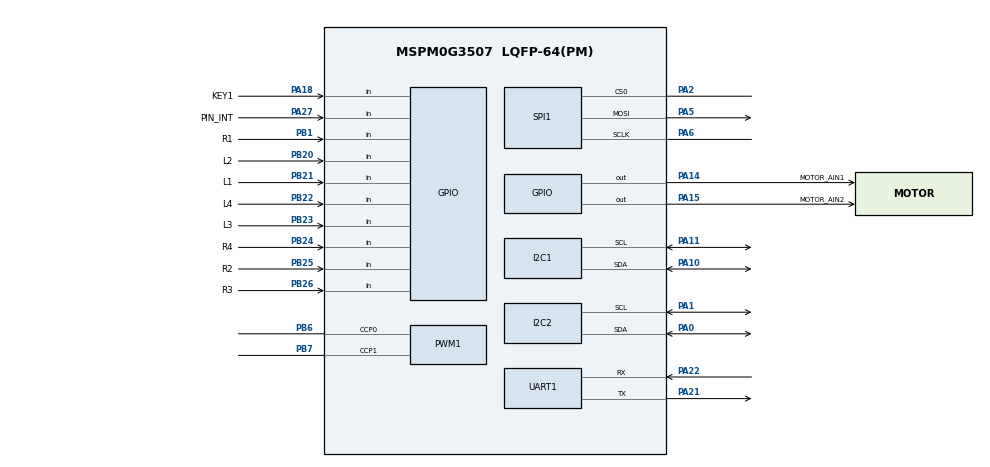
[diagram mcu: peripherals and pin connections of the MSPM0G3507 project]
/**
 * These arguments were used when this file was generated. They will be automatically applied on subsequent loads
 * via the GUI or CLI. Run CLI with '--help' for additional information on how to override these arguments.
 * @cliArgs --device "MSPM0G350X" --part "Default" --package "LQFP-64(PM)" --product "mspm0_sdk@2.10.00.04"
 * @v2CliArgs --device "MSPM0G3507" --package "LQFP-64(PM)" --product "mspm0_sdk@2.10.00.04"
 * @versions {"tool":"1.26.2+4477"}
 */

/**
 * Import the modules used in this configuration.
 */
const GPIO   = scripting.addModule("/ti/driverlib/GPIO", {}, false);
const GPIO1  = GPIO.addInstance();
const GPIO2  = GPIO.addInstance();
const GPIO3  = GPIO.addInstance();
const GPIO4  = GPIO.addInstance();
const GPIO5  = GPIO.addInstance();
const GPIO6  = GPIO.addInstance();
const GPIO7  = GPIO.addInstance();
const I2C    = scripting.addModule("/ti/driverlib/I2C", {}, false);
const I2C1   = I2C.addInstance();
const I2C2   = I2C.addInstance();
const PWM    = scripting.addModule("/ti/driverlib/PWM", {}, false);
const PWM1   = PWM.addInstance();
const SPI    = scripting.addModule("/ti/driverlib/SPI", {}, false);
const SPI1   = SPI.addInstance();
const SYSCTL = scripting.addModule("/ti/driverlib/SYSCTL");
const TIMER  = scripting.addModule("/ti/driverlib/TIMER", {}, false);
const TIMER1 = TIMER.addInstance();
const UART   = scripting.addModule("/ti/driverlib/UART", {}, false);
const UART1  = UART.addInstance();

/**
 * Write custom configuration values to the imported modules.
 */
GPIO1.port                           = "PORTB";
GPIO1.$name                          = "GPIO_RGB";
GPIO1.associatedPins[0].initialValue = "SET";
GPIO1.associatedPins[0].$name        = "GREEN";
GPIO1.associatedPins[0].assignedPin  = "27                                    ";

const Board = scripting.addModule("/ti/driverlib/Board", {}, false);

GPIO2.$name                              = "GPIO_BUTTON";
GPIO2.port                               = "PORTA";
GPIO2.associatedPins[0].$name            = "KEY1";
GPIO2.associatedPins[0].internalResistor = "PULL_DOWN";
GPIO2.associatedPins[0].direction        = "INPUT";
GPIO2.associatedPins[0].assignedPin      = "18";
GPIO2.associatedPins[0].pin.$assign      = "PA18";

GPIO3.port                          = "PORTA";
GPIO3.$name                         = "MOTOR_AIN";
GPIO3.associatedPins.create(2);
GPIO3.associatedPins[0].$name       = "MOTOR_AIN1";
GPIO3.associatedPins[0].assignedPin = "14";
GPIO3.associatedPins[0].pin.$assign = "PA14";
GPIO3.associatedPins[1].$name       = "MOTOR_AIN2";
GPIO3.associatedPins[1].assignedPin = "15";
GPIO3.associatedPins[1].pin.$assign = "PA15";

GPIO4.port                          = "PORTA";
GPIO4.$name                         = "MOTOR_BIN";
GPIO4.associatedPins.create(2);
GPIO4.associatedPins[0].assignedPin = "12";
GPIO4.associatedPins[0].$name       = "MOTOR_BIN1";
GPIO4.associatedPins[1].assignedPin = "13";
GPIO4.associatedPins[1].$name       = "MOTOR_BIN2";

GPIO5.$name                              = "GPIO_GRAY";
GPIO5.port                               = "PORTB";
GPIO5.associatedPins.create(8);
GPIO5.associatedPins[0].$name            = "L1";
GPIO5.associatedPins[0].direction        = "INPUT";
GPIO5.associatedPins[0].assignedPin      = "21";
GPIO5.associatedPins[0].internalResistor = "PULL_DOWN";
GPIO5.associatedPins[0].pin.$assign      = "PB21";
GPIO5.associatedPins[1].$name            = "L2";
GPIO5.associatedPins[1].direction        = "INPUT";
GPIO5.associatedPins[1].assignedPin      = "20";
GPIO5.associatedPins[1].internalResistor = "PULL_DOWN";
GPIO5.associatedPins[1].pin.$assign      = "PB20";
GPIO5.associatedPins[2].$name            = "L3";
GPIO5.associatedPins[2].direction        = "INPUT";
GPIO5.associatedPins[2].assignedPin      = "23";
GPIO5.associatedPins[2].internalResistor = "PULL_DOWN";
GPIO5.associatedPins[2].pin.$assign      = "PB23";
GPIO5.associatedPins[3].$name            = "L4";
GPIO5.associatedPins[3].direction        = "INPUT";
GPIO5.associatedPins[3].assignedPin      = "22";
GPIO5.associatedPins[3].internalResistor = "PULL_DOWN";
GPIO5.associatedPins[3].pin.$assign      = "PB22";
GPIO5.associatedPins[4].$name            = "R4";
GPIO5.associatedPins[4].direction        = "INPUT";
GPIO5.associatedPins[4].assignedPin      = "24";
GPIO5.associatedPins[4].internalResistor = "PULL_DOWN";
GPIO5.associatedPins[4].pin.$assign      = "PB24";
GPIO5.associatedPins[5].$name            = "R3";
GPIO5.associatedPins[5].direction        = "INPUT";
GPIO5.associatedPins[5].assignedPin      = "26";
GPIO5.associatedPins[5].internalResistor = "PULL_DOWN";
GPIO5.associatedPins[5].pin.$assign      = "PB26";
GPIO5.associatedPins[6].$name            = "R2";
GPIO5.associatedPins[6].direction        = "INPUT";
GPIO5.associatedPins[6].assignedPin      = "25";
GPIO5.associatedPins[6].internalResistor = "PULL_DOWN";
GPIO5.associatedPins[6].pin.$assign      = "PB25";
GPIO5.associatedPins[7].$name            = "R1";
GPIO5.associatedPins[7].direction        = "INPUT";
GPIO5.associatedPins[7].assignedPin      = "1";
GPIO5.associatedPins[7].internalResistor = "PULL_DOWN";
GPIO5.associatedPins[7].pin.$assign      = "PB1";

GPIO6.$name                               = "GPIO_MPU6050";
GPIO6.associatedPins[0].$name             = "PIN_INT";
GPIO6.associatedPins[0].direction         = "INPUT";
GPIO6.associatedPins[0].internalResistor  = "PULL_UP";
GPIO6.associatedPins[0].interruptEn       = true;
GPIO6.associatedPins[0].interruptPriority = "2";
GPIO6.associatedPins[0].polarity          = "FALL";
GPIO6.associatedPins[0].assignedPort      = "PORTA";
GPIO6.associatedPins[0].assignedPin       = "27";
GPIO6.associatedPins[0].pin.$assign       = "PA27";

GPIO7.$name                   = "GPIO_GRP_0";
GPIO7.associatedPins[0].$name = "PIN_0";

I2C1.$name                             = "I2C_OLED";
I2C1.basicEnableController             = true;
I2C1.basicControllerStandardBusSpeed   = "Fast";
I2C1.peripheral.$assign                = "I2C1";
I2C1.peripheral.sdaPin.$assign         = "PA10";
I2C1.peripheral.sclPin.$assign         = "PA11";
I2C1.sdaPinConfig.hideOutputInversion  = scripting.forceWrite(false);
I2C1.sdaPinConfig.onlyInternalResistor = scripting.forceWrite(false);
I2C1.sdaPinConfig.passedPeripheralType = scripting.forceWrite("Digital");
I2C1.sdaPinConfig.$name                = "ti_driverlib_gpio_GPIOPinGeneric2";
I2C1.sclPinConfig.hideOutputInversion  = scripting.forceWrite(false);
I2C1.sclPinConfig.onlyInternalResistor = scripting.forceWrite(false);
I2C1.sclPinConfig.passedPeripheralType = scripting.forceWrite("Digital");
I2C1.sclPinConfig.$name                = "ti_driverlib_gpio_GPIOPinGeneric3";

I2C2.$name                             = "I2C_MPU6050";
I2C2.basicEnableController             = true;
I2C2.basicControllerStandardBusSpeed   = "Fast";
I2C2.peripheral.$assign                = "I2C0";
I2C2.peripheral.sdaPin.$assign         = "PA0";
I2C2.peripheral.sclPin.$assign         = "PA1";
I2C2.sdaPinConfig.hideOutputInversion  = scripting.forceWrite(false);
I2C2.sdaPinConfig.onlyInternalResistor = scripting.forceWrite(false);
I2C2.sdaPinConfig.passedPeripheralType = scripting.forceWrite("Digital");
I2C2.sdaPinConfig.$name                = "ti_driverlib_gpio_GPIOPinGeneric4";
I2C2.sclPinConfig.hideOutputInversion  = scripting.forceWrite(false);
I2C2.sclPinConfig.onlyInternalResistor = scripting.forceWrite(false);
I2C2.sclPinConfig.passedPeripheralType = scripting.forceWrite("Digital");
I2C2.sclPinConfig.$name                = "ti_driverlib_gpio_GPIOPinGeneric5";

PWM1.$name                              = "PWM_MOTOR";
PWM1.pwmMode                            = "EDGE_ALIGN_UP";
PWM1.timerStartTimer                    = true;
PWM1.peripheral.$assign                 = "TIMG6";
PWM1.peripheral.ccp0Pin.$assign         = "PB6";
PWM1.peripheral.ccp1Pin.$assign         = "PB7";
PWM1.PWM_CHANNEL_0.$name                = "ti_driverlib_pwm_PWMTimerCC0";
PWM1.PWM_CHANNEL_0.dutyCycle            = 50;
PWM1.PWM_CHANNEL_1.$name                = "ti_driverlib_pwm_PWMTimerCC1";
PWM1.ccp0PinConfig.direction            = scripting.forceWrite("OUTPUT");
PWM1.ccp0PinConfig.hideOutputInversion  = scripting.forceWrite(false);
PWM1.ccp0PinConfig.onlyInternalResistor = scripting.forceWrite(false);
PWM1.ccp0PinConfig.passedPeripheralType = scripting.forceWrite("Digital");
PWM1.ccp0PinConfig.$name                = "ti_driverlib_gpio_GPIOPinGeneric0";
PWM1.ccp1PinConfig.direction            = scripting.forceWrite("OUTPUT");
PWM1.ccp1PinConfig.hideOutputInversion  = scripting.forceWrite(false);
PWM1.ccp1PinConfig.onlyInternalResistor = scripting.forceWrite(false);
PWM1.ccp1PinConfig.passedPeripheralType = scripting.forceWrite("Digital");
PWM1.ccp1PinConfig.$name                = "ti_driverlib_gpio_GPIOPinGeneric1";

SPI1.$name                      = "SPI_0";
SPI1.peripheral.$assign         = "SPI0";
SPI1.peripheral.sclkPin.$assign = "PA6";
SPI1.peripheral.mosiPin.$assign = "PA5";
SPI1.peripheral.cs0Pin.$assign  = "PA2";
SPI1.sclkPinConfig.$name        = "ti_driverlib_gpio_GPIOPinGeneric8";
SPI1.mosiPinConfig.$name        = "ti_driverlib_gpio_GPIOPinGeneric9";
SPI1.misoPinConfig.$name        = "ti_driverlib_gpio_GPIOPinGeneric10";
SPI1.cs0PinConfig.$name         = "ti_driverlib_gpio_GPIOPinGeneric11";

SYSCTL.forceDefaultClkConfig = true;

TIMER1.timerMode          = "PERIODIC";
TIMER1.timerStartTimer    = true;
TIMER1.$name              = "CONTROL_TIMER";
TIMER1.timerPeriod        = "10ms";
TIMER1.timerClkDiv        = 8;
TIMER1.interrupts         = ["ZERO"];
TIMER1.interruptPriority  = "2";
TIMER1.peripheral.$assign = "TIMA0";

UART1.$name                    = "UART_0";
UART1.targetBaudRate           = 115200;
UART1.peripheral.rxPin.$assign = "PA22";
UART1.peripheral.txPin.$assign = "PA21";
UART1.txPinConfig.$name        = "ti_driverlib_gpio_GPIOPinGeneric6";
UART1.rxPinConfig.$name        = "ti_driverlib_gpio_GPIOPinGeneric7";

/**
 * Pinmux solution for unlocked pins/peripherals. This ensures that minor changes to the automatic solver in a future
 * version of the tool will not impact the pinmux you originally saw.  These lines can be completely deleted in order to
 * re-solve from scratch.
 */
GPIO1.associatedPins[0].pin.$suggestSolution = "PB27";
Board.peripheral.$suggestSolution            = "DEBUGSS";
Board.peripheral.swclkPin.$suggestSolution   = "PA20";
Board.peripheral.swdioPin.$suggestSolution   = "PA19";
GPIO4.associatedPins[0].pin.$suggestSolution = "PA12";
GPIO4.associatedPins[1].pin.$suggestSolution = "PA13";
GPIO7.associatedPins[0].pin.$suggestSolution = "PB13";
SPI1.peripheral.misoPin.$suggestSolution     = "PA4";
SYSCTL.peripheral.$suggestSolution           = "SYSCTL";
UART1.peripheral.$suggestSolution            = "UART2";
